# NANO103AE_v1 register map
File version: 1.0
Registers are 32-bit, read-write, reset 0x0 unless marked. A register's access mark holds for its fields unless they carry their own. Offsets are from the block's base; [hi:lo] are bit positions; {n}, {i} and the like mark numbered series; 'fields as' and 'values as' point back to an identical list.

## CLK — CLK Register Map
Base 0x50000200
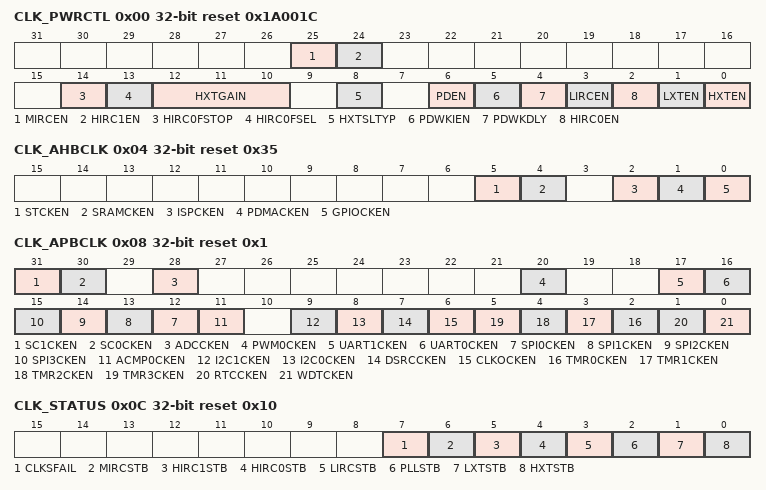
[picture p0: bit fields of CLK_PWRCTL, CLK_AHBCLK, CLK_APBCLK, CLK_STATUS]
0x00 CLK_PWRCTL reset 0x1A001C (reset mask 0xFFFF00FF) — System Power-down Control Register
  [25] MIRCEN — MIRC Enable Bit (Write Protect). Note: This bit is write protected. Refer to the SYS_REGLCTL register.
    0=4 MHz internal medium speed RC oscillator (MIRC)Disabled; 1=4 MHz internal medium speed RC oscillator (MIRC)Enabled
  [24] HIRC1EN — HIRC1 Enable Bit (Write Protect). Note: This bit is write protected. Refer to the SYS_REGLCTL register.
    0=36 MHz internal high speed RC oscillator (HIRC1)Disabled; 1=36 MHz internal high speed RC oscillator (HIRC1)Enabled
  [14] HIRC0FSTOP — HIRC0 Stop Output When Frequency Changes (Write Protect). Note: This bit is write protected. Refer to the SYS_REGLCTL register.
    0=HIRC0 will continue to output when HIRC frequency changes; 1=HIRC0will suppress to output during first 16 clocks when HIRC frequency change
  [13] HIRC0FSEL — HIRC0 Output Frequency Select Bit
    0=HIRC0 will output 12MHz clock; 1=HIRC0 will output 16MHz Clock
  [12:10] HXTGAIN — HXT Gain Control Bit(Write Protect). Gain control is used to enlarge the gain of crystal to make sure crystal wok normally. If gain control is enabled, crystal will consume more power than gain control off. Note: This bit is write protected. Refer to the SYS_REGLCTL register.
    0=HXT frequency is lower than from 4 MHz; 1=HXT frequency is from 4 MHz to 8 MHz; 2=HXT frequency is from 8 MHz to 12 MHz; 3=HXT frequency is from 12 MHz to 16 MHz; 4=HXT frequency is from 16 MHz to 24 MHz; 5=HXT frequency is from 24 MHz to 32 MHz; 6=HXT frequency is from 32 MHz to 36 MHz; 7=HXT frequency is higher than 36 MHz
  [8] HXTSLTYP — HXT Mode Selection (Write Protect). Note: This bit is write protected. Refer to the SYS_REGLCTL register.
    0=High frequency crystal loop back path Disabled. It is used for external oscillator; 1=High frequency crystal loop back path Enabled. It is used for external crystal
  [6] PDEN — System Power-down Enable (Write Protect). When this bit is set to 1, Power-down mode is enabled and chip Power-down behavior will depend on the PDWTCPU bit. (a) If the PDWTCPU is 0, then the chip enters Power-down mode immediately after the PDEN bit set. (default) (b) if the PDWTCPU is 1, then the chip keeps active till the CPU sleep mode is also active and then the chip enters Power-down mode. When chip wakes up from Power-down mode, this bit is auto cleared. Users need to set this bit again for next Power-down. In Power-down mode, HXT and the HIRC will be disabled in this mode, but LXT and LIRC are not controlled by Power-down mode. In Power-down mode, the PLL and system clock are disabled, and ignored the clock source selection. The clocks of peripheral are not controlled by Power-down mode, if the peripheral clock source is from LXT or LIRC. Note: This bit is write protected. Refer to the SYS_REGLCTL register.
    0=Chip operating normally or chip in idle mode because of WFI command; 1=Chip enters Power-down mode instant or wait CPU sleep command WFI
  [5] PDWKIEN — Power-down Mode Wake-up Interrupt Enable Bit (Write Protect). Note1: The interrupt (EINT0~1, GPIO,, UART0~1, WDT, ACMP01, BOD, RTC, TMR0~3, I2C0~1 or SPI0 ~3)will occur when PDWKIEN are high. Note2: This bit is write protected. Refer to the SYS_REGLCTL register.
    0=Power-down mode wake-up interrupt Disabled; 1=Power-down mode wake-up interrupt Enabled
  [4] PDWKDLY — Enable the Wake-up Delay Counter (Write Protect). When the chip wakes up from Power-down mode, the clock control will delay4096 clock cycles to wait system clock stable when chip works at 4~32 MHz external high speed crystal oscillator (HXT). Note: This bit is write protected. Refer to the SYS_REGLCTL register.
    0=Clock cycles delayDisabled; 1=Clock cycles delayEnabled
  [3] LIRCEN — LIRC Enable Bit(Write Protect). Note: This bit is write protected. Refer to the SYS_REGLCTL register.
    0=10 kHz internal low speed RC oscillator (LIRC) Disabled; 1=10 kHz internal low speed RC oscillator (LIRC)Enabled
  [2] HIRC0EN — HIRC0 Enable Bit (Write Protect). Note: This bit is write protected. Refer to the SYS_REGLCTL register.
    0=12~16 MHz internal high speed RC oscillator (HIRC0)Disabled; 1=12~16 MHz internal high speed RC oscillator (HIRC0)Enabled
  [1] LXTEN — LXT Enable Bit (Write Protect). Note: This bit is write protected. Refer to the SYS_REGLCTL register.
    0=32.768 kHz external lowspeed crystal (LXT) Disabled; 1=32.768 kHz external lowspeed crystal (LXT) Enabled
  [0] HXTEN — HXT Enable Bit (Write Protect). Note: This bit is write protected. Refer to the SYS_REGLCTL register.
    0=4~32 MHz external high speed crystal (HXT) Disabled; 1=4~32 MHz external high speed crystal (HXT) Enabled
0x04 CLK_AHBCLK reset 0x35 — AHB Devices Clock Enable Control Register
  [5] STCKEN — System Tick Clock Enable Control Bit
    0=System Tick Clock Disabled; 1=System Tick Clock Enabled
  [4] SRAMCKEN — SRAM Controller Clock Enable Control Bit
    0=SRAM peripheral clock Disabled; 1=SRAM peripheral clock Enabled
  [2] ISPCKEN — Flash ISP Controller Clock Enable Bit
    0=Flash ISP peripheral clock Disabled; 1=Flash ISP peripheral clock Enabled
  [1] PDMACKEN — PDMA Controller Clock Enable Bit
    0=PDMA peripheral clock Disabled; 1=PDMA peripheral clock Enabled
  [0] GPIOCKEN — GPIO Controller Clock Enable Control
    0=GPIO peripheral clock Disabled; 1=GPIO peripheral clock Enabled
0x08 CLK_APBCLK reset 0x1 — APB Devices Clock Enable Control Register
  [31] SC1CKEN — SmartCard 1 Clock Enable Control
    0=SmartCard 1 Clock Disabled; 1=SmartCard 1 Clock Enabled
  [30] SC0CKEN — SmartCard 0 Clock Enable Control
    0=SmartCard 0 Clock Disabled; 1=SmartCard 0 Clock Enabled
  [28] ADCCKEN — Analog-digital-converter (ADC) Clock Enable Control
    0=ADC Clock Disabled; 1=ADC Clock Enabled
  [20] PWM0CKEN — PWM0 Clock Enable Control
    0=PWM0 Clock Disabled; 1=PWM0 Clock Enabled
  [17] UART1CKEN — UART1 Clock Enable Control
    0=UART1 Clock Disabled; 1=UART1 Clock Enabled
  [16] UART0CKEN — UART0 Clock Enable Control
    0=UART0 Clock Disabled; 1=UART0 Clock Enabled
  [n+12] SPI{n}CKEN (n=0..3) — SPI{n} Clock Enable Control
    0=SPI{n} Clock Disabled; 1=SPI{n} Clock Enabled
  [11] ACMP0CKEN — ACMP0 Clock Enable Control
    0=ACMP0 Clock Disabled; 1=ACMP0 Clock Enabled
  [9] I2C1CKEN — I2C1 Clock Enable Control
    0=I2C1 Clock Disabled; 1=I2C1 Clock Enabled
  [8] I2C0CKEN — I2C0 Clock Enable Control
    0=I2C0 Clock Disabled; 1=I2C0 Clock Enabled
  [7] DSRCCKEN — DSRC Clock Enable Control
    0=DSRC Clock Disabled; 1=DSRC Clock Enabled
  [6] CLKOCKEN — ClocK Output Clock Enable Control
    0=Clock Output Clock Disabled; 1=Clock Output Clock Enabled
  [n+2] TMR{n}CKEN (n=0..3) — Timer{n} Clock Enable Control
    0=Timer{n} Clock Disabled; 1=Timer{n} Clock Enabled
  [1] RTCCKEN — Real-time-clock Clock Enable Control. This bit is used to control the RTC APB clock only, The RTC engine Clock Source is from LXT.
    0=Real-time-clock Clock Disabled; 1=Real-time-clock Clock Enabled
  [0] WDTCKEN — Watchdog Timer Clock Enable Control. This is a protected register. Please refer to open lock sequence to program it. This bit is used to control the WDT APB clock only, The WDT engine Clock Source is from LIRC.
    0=Watchdog Timer Clock Disabled; 1=Watchdog Timer Clock Enabled
0x0C CLK_STATUS ro reset 0x10 — Clock status monitor Register
  [7] CLKSFAIL — Clock Switching Fail Flag(Read Only). This bit is updated when software switches system clock source. If switch target clock is stable, this bit will be set to 0. If switch target clock is not stable, this bit will be set to 1.
    0=Clock switching success; 1=Clock switching failure
  [6] MIRCSTB — MIRCClock Source Stable Flag(Read Only)
    0=4 MHz internal medium speed RC oscillator (MIRC) clock is not stable or disabled; 1=4 MHz internal medium speed RC oscillator (MIRC) clock is stable and enabled
  [5] HIRC1STB — HIRCClock Source Stable Flag(Read Only)
    0=36 MHz internal high speed RC oscillator (HIRC1) clock is not stable or disabled; 1=36 MHz internal high speed RC oscillator (HIRC1) clock is stable and enabled
  [4] HIRC0STB — HIRC0 Clock Source Stable Flag (Read Only)
    0=12~16 MHz internal high speed RC oscillator (HIRC0) clock is not stable or disabled; 1=12~16 MHz internal high speed RC oscillator (HIRC0) clock is stable and enabled
  [3] LIRCSTB — LIRCClock Source Stable Flag(Read Only)
    0=10 kHz internal low speed RC oscillator (LIRC) clock is not stable or disabled; 1=10 kHz internal low speed RC oscillator (LIRC) clock is stable and enabled
  [2] PLLSTB — Internal PLL Clock Source Stable Flag(Read Only)
    0=Internal PLL clock is not stable or disabled; 1=Internal PLL clock is stable and enabled
  [1] LXTSTB — LXTClock Source Stable Flag(Read Only)
    0=32.768 kHz external low speed crystal oscillator (LXT) clock is not stable or disabled; 1=32.768 kHz external low speed crystal oscillator (LXT) clock is stabled and enabled
  [0] HXTSTB — HXTClock Source Stable Flag(Read Only)
    0=4~36 MHz external high speed crystal oscillator (HXT) clock is not stable or disabled; 1=4~36 MHz external high speed crystal oscillator (HXT)clock is stable and enabled
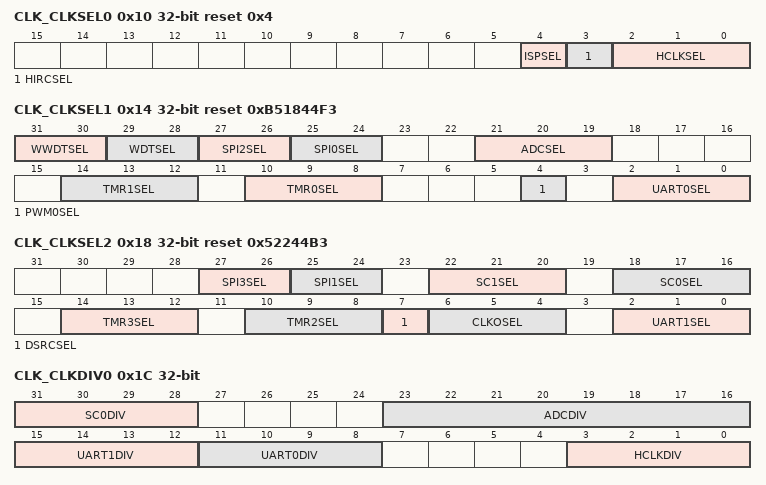
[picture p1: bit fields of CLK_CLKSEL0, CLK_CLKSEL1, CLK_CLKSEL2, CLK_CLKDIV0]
0x10 CLK_CLKSEL0 reset 0x4 — Clock Source Select Control Register 0
  [4] ISPSEL — ISP Clock Source Selection
    0=Clock source from HIRC1 or HIRC0 depend on HIRCSEL(CLK_CLKSEL0[3]) setting; 1=Clock source from MIRC
  [3] HIRCSEL — HIRC Source Selection
    0=Clock source from HIRC0 (12~16MHz); 1=Clock source from HIRC1 (36MHz)
  [2:0] HCLKSEL — HCLK Clock Source Selection(Write Protect). Before clock switching, the related clock sources (both pre-select and new-select) must be turned on. Note:This bit is write protected. Refer to the SYS_REGLCTL register.
    0=Clock source from HXT; 1=Clock source from LXT; 2=Clock source from PLL; 3=Clock source from LIRC; 4=Clock source from HIRC1 or HIRC0 depend on HIRCSEL(CLK_CLKSEL0[3]) setting
0x14 CLK_CLKSEL1 reset 0xB51844F3 — Clock Source Select Control Register 1
  [31:30] WWDTSEL — WDT Clock Source Selection
    2=Clock source from HCLK/2048; 3=Clock source from LIRC
  [29:28] WDTSEL — WDT Clock Source Selection
    1=Clock source from LXT; 2=Clock source from HCLK/2048; 3=Clock source from LIRC
  [27:26] SPI2SEL — SPI2 Clock Source Selection
    0=Clock source from PLL; 1=Clock source from HCLK; 2=Clock source from 4~32 MHz external high speed crystal oscillator (HXT); 3=Clock source from 36 MHz internal high speed RC oscillator (HIRC1) or HIRC0 depend on HIRCSEL(CLK_CLKSEL0[3]) setting
  [25:24] SPI0SEL — SPI0 Clock Source Selection
    values as SPI2SEL
  [21:19] ADCSEL — ADC Clock Source Selection
    0=Clock source from 4~32 MHz external high speed crystal oscillator (HXT); 1=Clock source from 32.768 kHz external low speed crystal oscillator (LXT); 2=Clock source from PLL; 3=Clock source from36 MHz internal high speed RC oscillator (HIRC1) or HIRC0 depend on HIRCSEL(CLK_CLKSEL0[3]) setting; 4=Clock source from 4 MHz internal medium speed RC oscillator (MIRC)
  [14:12] TMR1SEL — Timer1 Clock Source Selection
    0=Clock source from 4~32 MHz external high speed crystal oscillator (HXT); 1=Clock source from 32.768 kHz external low speed crystal oscillator (LXT); 2=Clock source from 10 kHz internal low speed RC oscillator (LIRC); 3=Clock source from external clock pin; 4=Clock source from36 MHz internal high speed RC oscillator (HIRC1) or HIRC0 depend on HIRCSEL(CLK_CLKSEL0[3]) setting; 5=Clock source from 4 MHz internal medium speed RC oscillator (MIRC)
  [10:8] TMR0SEL — Timer0 Clock Source Selection
    values as TMR1SEL
  [4] PWM0SEL — PWM0 Clock Source Selection
    0=Clock source from PLL; 1=Clock source from PCLK0
  [2:0] UART0SEL — UART0 Clock Source Selection
    0=Clock source from 4~32 MHz external high speed crystal oscillator (HXT); 1=Clock source from 32.768 kHz external low speed crystal oscillator (LXT); 2=Clock source from PLL; 3=Clock source from 36 MHz internal high speed RC oscillator (HIRC1) or HIRC0 depend on HIRCSEL(CLK_CLKSEL0[3]) setting
0x18 CLK_CLKSEL2 reset 0x52244B3 — Clock Source Select Control Register 2
  [27:26] SPI3SEL — SPI3 Clock Source Selection
    values as CLK_CLKSEL1.SPI2SEL
  [25:24] SPI1SEL — SPI1 Clock Source Selection
    values as CLK_CLKSEL1.SPI2SEL
  [22:20] SC1SEL — SC1 Clock Source Selection
    0=Clock source from 4~32 MHz external high speed crystal oscillator (HXT); 1=Clock source from PLL; 2=Clock source from 36 MHz internal high speed RC oscillator (HIRC1) or HIRC0 depend on HIRCSEL(CLK_CLKSEL0[3]) setting; 3=Clock source from 4 MHz internal medium speed RC oscillator (MIRC)
  [18:16] SC0SEL — SC0 Clock Source Selection
    values as SC1SEL
  [14:12] TMR3SEL — Timer3 Clock Source Selection
    values as CLK_CLKSEL1.TMR1SEL
  [10:8] TMR2SEL — Timer2 Clock Source Selection
    values as CLK_CLKSEL1.TMR1SEL
  [7] DSRCSEL — DSRC Clock Source Selection
    0=Clock source from 4 MHz internal medium speed RC oscillator (MIRC); 1=Clock source from 36 MHz internal high speed RC oscillator (HIRC1) or HIRC0 depend on HIRCSEL(CLK_CLKSEL0[3]) setting
  [6:4] CLKOSEL — Clock Divider Clock Source Selection
    0=Clock source from 4~32 MHz external high speed crystal oscillator (HXT); 1=Clock source from 32.768 kHz external low speed crystal oscillator (LXT); 2=Clock source from HCLK; 3=Clock source from36 MHz internal high speed RC oscillator (HIRC1) or HIRC0 depend on HIRCSEL(CLK_CLKSEL0[3]) setting
  [2:0] UART1SEL — UART1 Clock Source Selection
    values as CLK_CLKSEL1.UART0SEL
0x1C CLK_CLKDIV0 — Clock Divider Number Register 0
  [31:28] SC0DIV — SC0Clock Divide Number From SC0Clock Source
  [23:16] ADCDIV — ADC Clock Divide Number From ADC Clock Source
  [15:12] UART1DIV — UART1Clock Divide Number From UART Clock Source
  [11:8] UART0DIV — UART0Clock Divide Number From UART Clock Source
  [3:0] HCLKDIV — HCLK Clock Divide Number From HCLK Clock Source
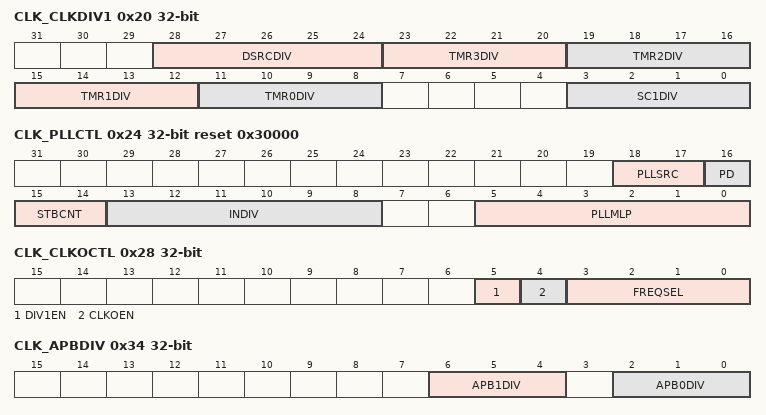
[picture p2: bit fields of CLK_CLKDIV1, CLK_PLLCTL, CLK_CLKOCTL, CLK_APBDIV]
0x20 CLK_CLKDIV1 — Clock Divider Number Register 1
  [28:24] DSRCDIV — DSRC Clock Divide Number From DSRCClock Source
  [4n+11:4n+8] TMR{n}DIV (n=0..3) — Timer{n}Clock Divide Number From Timer{n}Clock Source
  [3:0] SC1DIV — SC 1Clock Divide Number From SC 1Clock Source
0x24 CLK_PLLCTL reset 0x30000 — PLL Control Register
  [18:17] PLLSRC — PLL Source Clock Select
    0=PLL source clock from HXT; 1=PLL source clock from HIRC0 or HIRC1; 2=PLL source clock from MIRC
  [16] PD — Power-down Mode. If set the PDEN bit "1" in CLK_PWRCTL register, the PLL will enter Power-down mode too
    0=PLL is in normal mode; 1=PLL is in power-down mode (default)
  [15:14] STBCNT — PLL Stable Time Selection
    0=100 cycle time of input clock source; 1=120 cycle time of input clock source; 2=180 cycle time of input clock source; 3=240 cycle time of input clock source
  [13:8] INDIV — PLL Input Source Divider. PLL input clock frequency range: 0.8MHz ~ 2MHz
  [5:0] PLLMLP — PLL Multiple. 000000: Reserved. 000001: X1. 000010: X2. 000011: X3. 000100: X4 ... 010000:X16 ... 100000: X32. 100100: X36. 0thers: Reserved. PLL output frequency: PLL input frequency * PLLMLP. PLL output frequency range: 16MHz ~ 36MHz
0x28 CLK_CLKOCTL — Clock Output Control Register
  [5] DIV1EN — Clock Output Divide One Enable Bit
    0=Clock Output will output clock with source frequency divided by FREQSEL; 1=Clock Output will output clock with source frequency
  [4] CLKOEN — Clock Output Enable Bit
    0=Clock Output function Disabled; 1=Clock Output function Enabled
  [3:0] FREQSEL — Clock Output Frequency Selection. The formula of output frequency is. Fin is the input clock frequency. Fout is the frequency of divider output clock. N is the 4-bit value of FREQSEL[3:0].
0x30 CLK_WKINTSTS ro — Wake-up Interrupt Status
  [0] PDWKIF — Wake-up Interrupt Status in Chip Power-down Mode. This bit indicates that some event resumes chip from Power-down mode. The status is set if external interrupts, UART, GPIO, RTC, USB, SPI, Timer, WDT, and BOD wake-up occurred. Write 1 to clear this bit.
0x34 CLK_APBDIV — APB Clock Divider
  [6:4] APB1DIV — APB1 Clock Divider. APB1 PCLK1 can be divided from HCLK.
  [2:0] APB0DIV — APB0 Clock Divider. APB0 PCLK0 can be divided from HCLK.
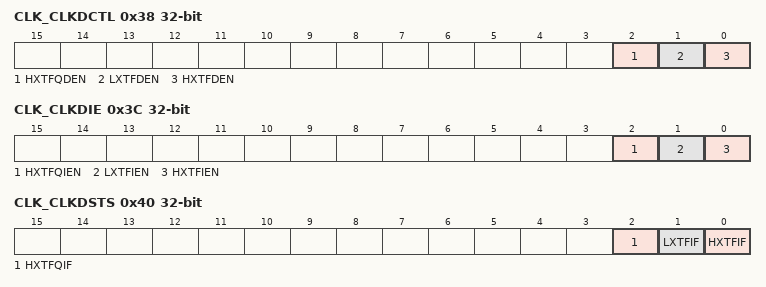
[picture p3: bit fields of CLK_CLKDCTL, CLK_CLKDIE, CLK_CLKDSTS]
0x38 CLK_CLKDCTL — Clock Fail Detector Control Register
  [2] HXTFQDEN — HXT Clock Frequency Monitor Enable Bit
    0=4~32 MHz external high speed crystal oscillator (HXT) clock frequency monitor Disabled; 1=4~32 MHz external high speed crystal oscillator (HXT) clock frequency monitor Enabled
  [1] LXTFDEN — LXT Clock Fail Detector Enable Bit
    0=32.768 kHz external low speed crystal oscillator (LXT) clock fail detector Disabled; 1=32.768 kHz external low speed crystal oscillator (LXT) clock fail detector Enabled
  [0] HXTFDEN — HXT Clock Fail Detector Enable Bit
    0=4~32 MHz external high speed crystal oscillator (HXT) clock fail detector Disabled; 1=4~32 MHz external high speed crystal oscillator (HXT) clock fail detector Enabled
0x3C CLK_CLKDIE — Clock Fail Detector Interrupt Enable Register
  [2] HXTFQIEN — HXT Clock Frequency Monitor Interrupt Enable Bit
    0=4~32 MHz external high speed crystal oscillator (HXT) clock frequency monitor fail interrupt Disabled; 1=4~32 MHz external high speed crystal oscillator (HXT) clock frequency monitor fail interrupt Enabled
  [1] LXTFIEN — LXT Clock Fail Interrupt Enable Bit
    0=32.768 kHz external low speed crystal oscillator (LXT) clock fail interrupt Disabled; 1=32.768 kHz external low speed crystal oscillator (LXT) clock fail interrupt Enabled
  [0] HXTFIEN — HXT Clock Fail Interrupt Enable Bit
    0=4~32 MHz external high speed crystal oscillator (HXT) clock fail interrupt Disabled; 1=4~32 MHz external high speed crystal oscillator (HXT) clock fail interrupt Enabled
0x40 CLK_CLKDSTS ro — Clock Fail Detector Status Register
  [2] HXTFQIF — HXT Clock Frequency Monitor Interrupt Flag. Note: Write 1 to clear the bit to 0.
    0=4~32 MHz external high speed crystal oscillator (HXT) clock is normal; 1=4~32 MHz external high speed crystal oscillator (HXT) clock frequency is abnormal
  [1] LXTFIF — LXT Clock Fail Interrupt Flag. Note: Write 1 to clear the bit to 0.
    0=32.768 kHz external low speed crystal oscillator (LXT) clock is normal; 1=32.768 kHz external low speed crystal oscillator (LXT) stops
  [0] HXTFIF — HXT Clock Fail Interrupt Flag. Note: Write 1 to clear the bit to 0.
    0=4~32 MHz external high speed crystal oscillator (HXT) clock is normal; 1=4~32 MHz external high speed crystal oscillator (HXT) clock stops
0x44 CLK_CDUPB — Clock Frequency Detector Upper Boundary Register
  [10:0] UPERBD — HXT Clock Frequency Detector Upper Boundary. The bits define the high value of frequency monitor window. When HXT frequency monitor value higher than this register, the HXT frequency detect fail interrupt flag will set to 1.
0x48 CLK_CDLOWB — Clock Frequency Detector Lower Boundary Register
  [10:0] LOWERBD — HXT Clock Frequency Detector Lower Boundary. The bits define the low value of frequency monitor window. When HXT frequency monitor value lower than this register, the HXT frequency detect fail interrupt flag will set to 1.
